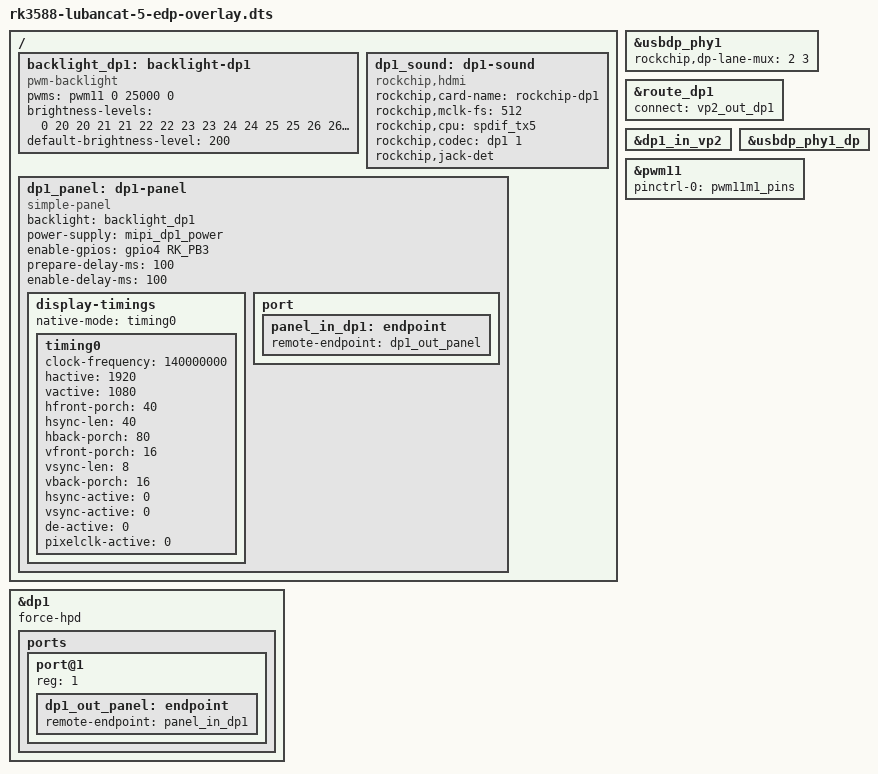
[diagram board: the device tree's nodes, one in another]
/dts-v1/;
/plugin/;

#include <dt-bindings/gpio/gpio.h>
#include <dt-bindings/pinctrl/rockchip.h>
#include <dt-bindings/display/drm_mipi_dsi.h>
#include <dt-bindings/interrupt-controller/irq.h>

/ {
	fragment@0 {
		target = <&usbdp_phy1>;

		__overlay__ {
			rockchip,dp-lane-mux = <2 3>;
		};
	};

	fragment@1 {
		target = <&route_dp1>;

		__overlay__ {
			status = "okay";
			connect = <&vp2_out_dp1>;
		};
	};

	fragment@2 {
		target = <&dp1_in_vp2>;

		__overlay__ {
			status = "okay";
		};
	};

	fragment@3 {
		target = <&usbdp_phy1_dp>;

		__overlay__ {
			status = "okay";
		};
	};

	fragment@4 {
		target = <&dp1>;

		__overlay__ {
			
			force-hpd; 
			status = "okay";
			ports {
				#address-cells = <1>;
				#size-cells = <0>;
				port@1 {
					reg = <1>;

					dp1_out_panel: endpoint {
						remote-endpoint = <&panel_in_dp1>;
					};
				};
			};
		};
	};

	fragment@5 {
		target-path = "/";

		__overlay__ {
			backlight_dp1: backlight-dp1 {
				compatible = "pwm-backlight";
				pwms = <&pwm11 0 25000 0>;
				brightness-levels = <
				0  20  20  21  21  22  22  23
				23  24  24  25  25  26  26  27
				27  28  28  29  29  30  30  31
				31  32  32  33  33  34  34  35
				35  36  36  37  37  38  38  39
				40  41  42  43  44  45  46  47
				48  49  50  51  52  53  54  55
				56  57  58  59  60  61  62  63
				64  65  66  67  68  69  70  71
				72  73  74  75  76  77  78  79
				80  81  82  83  84  85  86  87
				88  89  90  91  92  93  94  95
				96  97  98  99 100 101 102 103
				104 105 106 107 108 109 110 111
				112 113 114 115 116 117 118 119
				120 121 122 123 124 125 126 127
				128 129 130 131 132 133 134 135
				136 137 138 139 140 141 142 143
				144 145 146 147 148 149 150 151
				152 153 154 155 156 157 158 159
				160 161 162 163 164 165 166 167
				168 169 170 171 172 173 174 175
				176 177 178 179 180 181 182 183
				184 185 186 187 188 189 190 191
				192 193 194 195 196 197 198 199
				200 201 202 203 204 205 206 207
				208 209 210 211 212 213 214 215
				216 217 218 219 220 221 222 223
				224 225 226 227 228 229 230 231
				232 233 234 235 236 237 238 239
				240 241 242 243 244 245 246 247
				248 249 250 251 252 253 254 255	
				>;
				default-brightness-level = <200>;
			};

			dp1_sound: dp1-sound {
				status = "okay";
				compatible = "rockchip,hdmi";
				rockchip,card-name= "rockchip-dp1";
				rockchip,mclk-fs = <512>;
				rockchip,cpu = <&spdif_tx5>;
				rockchip,codec = <&dp1 1>;
				rockchip,jack-det;
			};

			dp1_panel: dp1-panel {
				status = "okay";
				compatible = "simple-panel";
				backlight = <&backlight_dp1>;
				power-supply = <&mipi_dp1_power>;
				enable-gpios = <&gpio4 RK_PB3 GPIO_ACTIVE_HIGH>;

				prepare-delay-ms = <100>; //AUX通信前延时
				enable-delay-ms = <100>;

				display-timings {
					native-mode = <&timing0>;

					timing0: timing0 {
						clock-frequency = <140000000>;
						hactive = <1920>;
						vactive = <1080>;
						hfront-porch = <40>;
						hsync-len = <40>;
						hback-porch = <80>;
						vfront-porch = <16>;
						vsync-len = <8>;
						vback-porch = <16>;
						hsync-active = <0>;
						vsync-active = <0>;
						de-active = <0>;
						pixelclk-active = <0>;
					};
				};

				port {
					panel_in_dp1: endpoint {
						remote-endpoint = <&dp1_out_panel>;
					};
				};
			};
		};
	};

	fragment@6 {
		target = <&pwm11>;

		__overlay__ {
			pinctrl-0 = <&pwm11m1_pins>;
			status = "okay";
		};
	};
};

